# ATSAMG55G19 register map
Vendor: Atmel; Series: SAMG55; File version: 0
CPU: CM4 r0p1, selectable endian, MPU, FPU, 4 interrupt priority bits
Registers are 32-bit, read-write, reset 0x0 unless marked. A register's access mark holds for its fields unless they carry their own. Offsets are from the block's base; [hi:lo] are bit positions.

## FLEXCOM5 — Flexible Serial Communication 5
Base 0x40008000; register names take the prefix FLEXCOM5_
0x00 MR — FLEXCOM Mode register
  [1:0] OPMODE — FLEXCOM Operating Mode
    0=NO_COM (No communication); 1=USART (All related USART related protocols are selected (RS232, RS485, IrDA, ISO7816, LIN,)All SPI/TWI related registers are not accessible and have no impact on IOs.); 2=SPI (SPI operating mode is selected.All USART/TWI related registers are not accessible and have no impact on IOs.); 3=TWI (All related TWI protocols are selected (TWI, SMBUS). All USART/SPI related registers are not accessible and have no impact on IOs.)
0x10 RHR ro — FLEXCOM Receive Holding Register
  [15:0] RXDATA — Receive Data
0x20 THR — FLEXCOM Transmit Holding Register
  [15:0] TXDATA — Transmit Data

## FLEXCOM0 — Flexible Serial Communication 0
Base 0x4000C000; register names take the prefix FLEXCOM0_
Registers as FLEXCOM5.

## FLEXCOM3 — Flexible Serial Communication 3
Base 0x40018000; register names take the prefix FLEXCOM3_
Registers as FLEXCOM5.

## FLEXCOM4 — Flexible Serial Communication 4
Base 0x4001C000; register names take the prefix FLEXCOM4_
Registers as FLEXCOM5.

## FLEXCOM1 — Flexible Serial Communication 1
Base 0x40020000; register names take the prefix FLEXCOM1_
Registers as FLEXCOM5.

## FLEXCOM2 — Flexible Serial Communication 2
Base 0x40024000; register names take the prefix FLEXCOM2_
Registers as FLEXCOM5.

## FLEXCOM7 — Flexible Serial Communication 7
Base 0x40034000; register names take the prefix FLEXCOM7_
Registers as FLEXCOM5.

## FLEXCOM6 — Flexible Serial Communication 6
Base 0x40040000; register names take the prefix FLEXCOM6_
Registers as FLEXCOM5.

## PDMIC0 — Pulse Density Modulation Interface Controller 0
Base 0x4002C000; register names take the prefix PDMIC0_
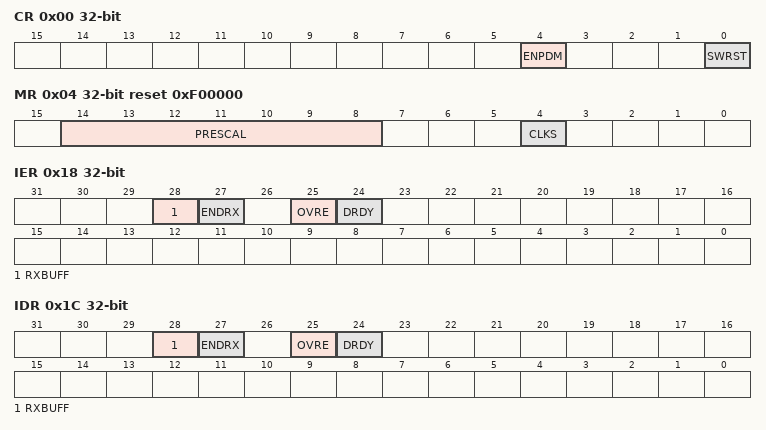
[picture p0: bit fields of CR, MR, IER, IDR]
0x00 CR — Control Register
  [4] ENPDM — Enable PDM
  [0] SWRST — Software Reset
0x04 MR reset 0xF00000 — Mode Register
  [14:8] PRESCAL — Prescaler Rate Selection
  [4] CLKS — Clock Source Selection
0x14 CDR ro — Converted Data Register
  [31:0] DATA — Data Converted
0x18 IER wo reset not defined — Interrupt Enable Register
  [28] RXBUFF — Receive Buffer Full Interrupt Enable
  [27] ENDRX — End of Receive Buffer Interrupt Enable
  [25] OVRE — Overrun Error Interrupt Enable
  [24] DRDY — Data Ready Interrupt Enable
0x1C IDR wo reset not defined — Interrupt Disable Register
  [28] RXBUFF — Receive Buffer Full Interrupt Disable
  [27] ENDRX — End of Receive Buffer Interrupt Disable
  [25] OVRE — General Overrun Error Interrupt Disable
  [24] DRDY — Data Ready Interrupt Disable
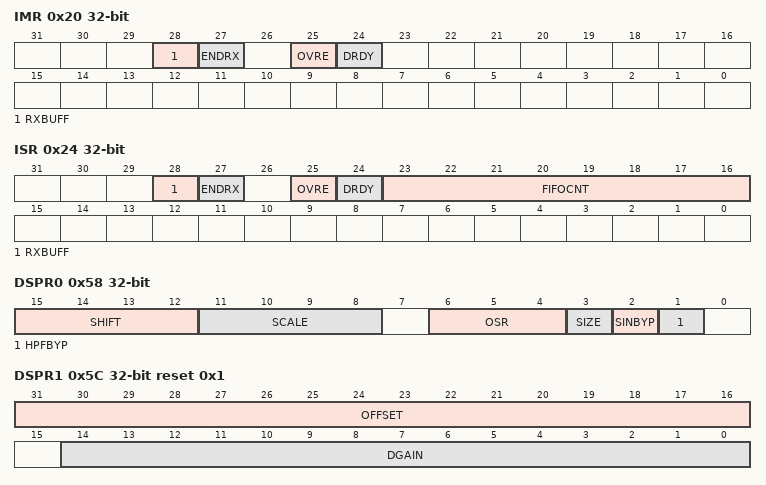
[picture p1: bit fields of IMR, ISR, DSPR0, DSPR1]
0x20 IMR ro — Interrupt Mask Register
  [28] RXBUFF — Receive Buffer Full Interrupt Mask
  [27] ENDRX — End of Receive Buffer Interrupt Mask
  [25] OVRE — General Overrun Error Interrupt Mask
  [24] DRDY — Data Ready Interrupt Mask
0x24 ISR ro — Interrupt Status Register
  [28] RXBUFF — RX Buffer Full
  [27] ENDRX — End of RX Buffer
  [25] OVRE — Overrun Error
  [24] DRDY — Data Ready
  [23:16] FIFOCNT — FIFO Count
0x58 DSPR0 — DSP Configuration Register 0
  [15:12] SHIFT — Data Shift
  [11:8] SCALE — Data Scale
  [6:4] OSR — Oversampling Ratio
    0=Oversampling ratio is 128; 1=Oversampling ratio is 64
  [3] SIZE — Data Size
  [2] SINBYP — SINCC Filter Bypass
  [1] HPFBYP — High-Pass Filter Bypass
0x5C DSPR1 reset 0x1 — DSP Configuration Register 1
  [31:16] OFFSET — Offset Correction
  [14:0] DGAIN — Gain Correction
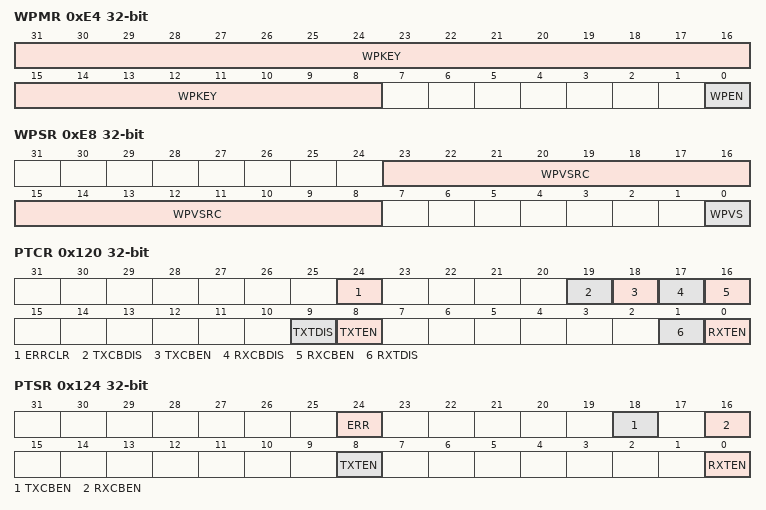
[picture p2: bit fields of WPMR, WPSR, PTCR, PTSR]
0xE4 WPMR — Write Protection Mode Register
  [31:8] WPKEY — Write Protect Key
    0x414443=PASSWD (Writing any other value in this field aborts the write operation of the WPEN bit.Always reads as 0.)
  [0] WPEN — Write Protection Enable
0xE8 WPSR ro — Write Protection Status Register
  [23:8] WPVSRC — Write Protection Violation Source
  [0] WPVS — Write Protection Violation Status
0x100 RPR — Receive Pointer Register
  [31:0] RXPTR
0x104 RCR — Receive Counter Register
  [15:0] RXCTR
0x110 RNPR — Receive Next Pointer Register
  [31:0] RXNPTR — Receive Next Pointer
0x114 RNCR — Receive Next Counter Register
  [15:0] RXNCTR — Receive Next Counter
0x120 PTCR wo reset not defined — Transfer Control Register
  [24] ERRCLR — Transfer Bus Error Clear
  [19] TXCBDIS — Transmitter Circular Buffer Disable
  [18] TXCBEN — Transmitter Circular Buffer Enable
  [17] RXCBDIS — Receiver Circular Buffer Disable
  [16] RXCBEN — Receiver Circular Buffer Enable
  [9] TXTDIS — Transmitter Transfer Disable
  [8] TXTEN — Transmitter Transfer Enable
  [1] RXTDIS — Receiver Transfer Disable
  [0] RXTEN — Receiver Transfer Enable
0x124 PTSR ro — Transfer Status Register
  [24] ERR — Transfer Bus Error
  [18] TXCBEN — Transmitter Circular Buffer Enable
  [16] RXCBEN — Receiver Circular Buffer Enable
  [8] TXTEN — Transmitter Transfer Enable
  [0] RXTEN — Receiver Transfer Enable

## PDMIC1 — Pulse Density Modulation Interface Controller 1
Base 0x40030000; register names take the prefix PDMIC1_
Registers as PDMIC0.
